# STM32F479xx register map
File version: 1.0
Registers are 32-bit, read-write, reset 0x0 unless marked. A register's access mark holds for its fields unless they carry their own. Offsets are from the block's base; [hi:lo] are bit positions; lines under a group give offsets from that group; {n}, {i} and the like mark numbered series.

## DAC — Digital to Analog Converter
Base 0x40007400
Same registers: DAC1 0x40007400 (alternate view of DAC)
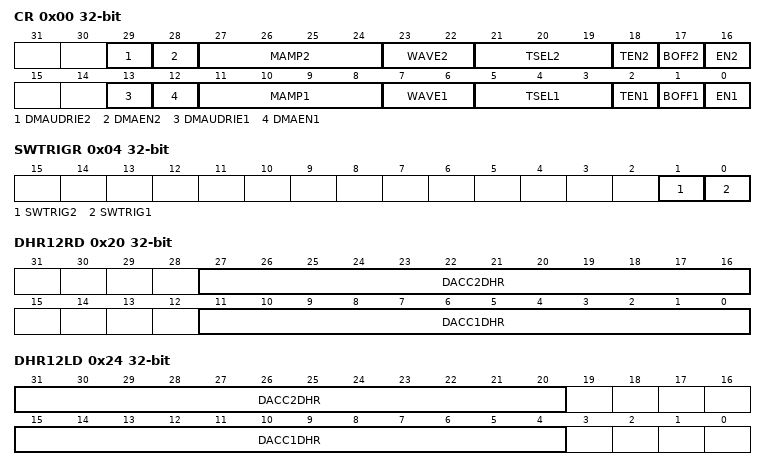
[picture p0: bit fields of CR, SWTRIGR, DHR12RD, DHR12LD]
0x00 CR — DAC control register
  [29] DMAUDRIE2 — DAC channel2 DMA underrun interrupt enable
  [28] DMAEN2 — DAC channel2 DMA enabled
  [27:24] MAMP2 — MAMP2[3:0] (DAC channel2 Mask/Amplitude selector)
  [23:22] WAVE2 — WAVE2[1:0] (DAC channel2 noise/triangle wave generation enable)
  [21:19] TSEL2 — TSEL2[2:0] (DAC channel2 Trigger selection)
  [18] TEN2 — DAC channel2 Trigger enable
  [17] BOFF2 — DAC channel2 output buffer disable
  [16] EN2 — DAC channel2 enable
  [13] DMAUDRIE1 — DAC channel1 DMA underrun interrupt enable
  [12] DMAEN1 — DAC channel1 DMA enable
  [11:8] MAMP1 — MAMP1[3:0] (DAC channel1 Mask/Amplitude selector)
  [7:6] WAVE1 — WAVE1[1:0] (DAC channel1 noise/triangle wave generation enable)
  [5:3] TSEL1 — TSEL1[2:0] (DAC channel1 Trigger selection)
  [2] TEN1 — DAC channel1 Trigger enable
  [1] BOFF1 — DAC channel1 output buffer disable
  [0] EN1 — DAC channel1 enable
0x04 SWTRIGR — DAC software trigger register
  [1] SWTRIG2 — DAC channel2 software trigger
  [0] SWTRIG1 — DAC channel1 software trigger
0x08 DHR12R1 — DAC channel1 12-bit right-aligned data holding register
  [11:0] DACC1DHR — DAC channel1 12-bit Right aligned data
0x0C DHR12L1 — DAC channel1 12-bit left aligned data holding register
  [15:4] DACC1DHR — DAC channel1 12-bit Left aligned data
0x10 DHR8R1 — DAC channel1 8-bit right aligned data holding register
  [7:0] DACC1DHR — DAC channel1 8-bit Right aligned data
0x14 DHR12R2 — DAC channel2 12-bit right aligned data holding register
  [11:0] DACC2DHR — DAC channel2 12-bit Right aligned data
0x18 DHR12L2 — DAC channel2 12-bit left aligned data holding register
  [15:4] DACC2DHR — DAC channel2 12-bit Left aligned data
0x1C DHR8R2 — DAC channel2 8-bit right-aligned data holding register
  [7:0] DACC2DHR — DAC channel2 8-bit Right aligned data
0x20 DHR12RD — Dual DAC 12-bit right-aligned data holding register
  [27:16] DACC2DHR — DAC channel2 12-bit Right aligned data
  [11:0] DACC1DHR — DAC channel1 12-bit Right aligned data
0x24 DHR12LD — DUAL DAC 12-bit left aligned data holding register
  [31:20] DACC2DHR — DAC channel2 12-bit Left aligned data
  [15:4] DACC1DHR — DAC channel1 12-bit Left aligned data
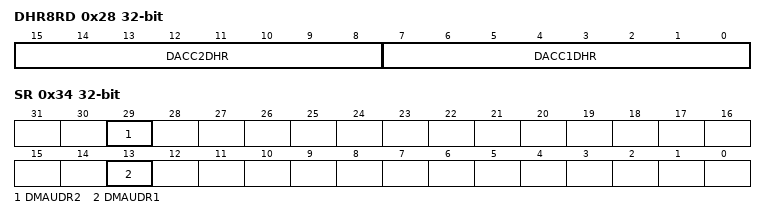
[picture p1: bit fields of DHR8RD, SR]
0x28 DHR8RD — DUAL DAC 8-bit right aligned data holding register
  [15:8] DACC2DHR — DAC channel2 8-bit Right aligned data
  [7:0] DACC1DHR — DAC channel1 8-bit Right aligned data
0x2C DOR1 — DAC channel1 data output register
  [11:0] DACC1DOR — DAC channel1 data output
0x30 DOR2 — DAC channel2 data output register
  [11:0] DACC2DOR — DAC channel2 data output
0x34 SR — DAC status register
  [29] DMAUDR2 — DAC channel2 DMA underrun flag
  [13] DMAUDR1 — DAC channel1 DMA underrun flag

## ADC123_COMMON
Base 0x40012300
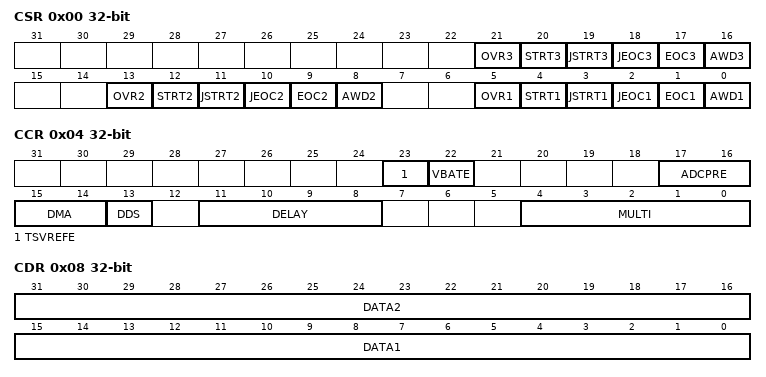
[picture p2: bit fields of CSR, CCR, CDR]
0x00 CSR — ADC Common status register
  [21] OVR3 — ADC3 DMA overrun flag
  [20] STRT3 — ADC3 Regular channel Start flag
  [19] JSTRT3 — ADC3 Injected channel Start flag
  [18] JEOC3 — ADC3 Injected channel end of conversion
  [17] EOC3 — ADC3 End of conversion
  [16] AWD3 — ADC3 Analog watchdog flag
  [13] OVR2 — ADC2 DMA overrun flag
  [12] STRT2 — ADC2 Regular channel Start flag
  [11] JSTRT2 — ADC2 Injected channel Start flag
  [10] JEOC2 — ADC2 Injected channel end of conversion
  [9] EOC2 — ADC2 End of conversion
  [8] AWD2 — ADC2 Analog watchdog flag
  [5] OVR1 — ADC1 DMA overrun flag
  [4] STRT1 — ADC1 Regular channel Start flag
  [3] JSTRT1 — ADC1 Injected channel Start flag
  [2] JEOC1 — ADC1 Injected channel end of conversion
  [1] EOC1 — ADC1 End of conversion
  [0] AWD1 — ADC1 Analog watchdog flag
0x04 CCR — ADC common control register
  [23] TSVREFE — Temperature Sensor and VREFINT Enable
  [22] VBATE — VBAT Enable
  [17:16] ADCPRE — ADCPRE[1:0] bits (ADC prescaler)
    0=DIV2 (ADC synchronous clock derived from AHB clock with prescaler division by 2); 1=DIV4 (ADC synchronous clock derived from AHB clock with prescaler division by 4); 2=DIV6 (ADC synchronous clock derived from AHB clock with prescaler division by 6); 3=DIV8 (ADC synchronous clock derived from AHB clock with prescaler division by 8)
  [15:14] DMA — DMA[1:0] bits (Direct Memory Access mode for multimode)
  [13] DDS — DMA disable selection (Multi-ADC mode)
  [11:8] DELAY — DELAY[3:0] bits (Delay between 2 sampling phases)
    {v}=DELAY_{v+5}CYCLES (ADC multimode delay between two sampling phases: {v+5} ADC clock cycles) (v=0..15)
  [4:0] MULTI — MULTI[4:0] bits (Multi-ADC mode selection)
    0=INDEPENDENT (ADC dual mode disabled (ADC independent mode)); 6=DUAL_REG_SIMULT (ADC dual mode enabled: group regular simultaneous); 7=DUAL_REG_INTERL (ADC dual mode enabled: Combined group regular interleaved); 5=DUAL_INJ_SIMULT (ADC dual mode enabled: group injected simultaneous); 9=DUAL_INJ_ALTERN (ADC dual mode enabled: group injected alternate trigger. Works only with external triggers (not internal SW start)); 1=DUAL_REG_SIM_INJ_SIM (ADC dual mode enabled: Combined group regular simultaneous + group injected simultaneous); 2=DUAL_REG_SIM_INJ_ALT (ADC dual mode enabled: Combined group regular simultaneous + group injected alternate trigger); 3=DUAL_REG_INT_INJ_SIM (ADC dual mode enabled: Combined group regular interleaved + group injected simultaneous); 17=TRIPLE_REG_SIM_INJ_SIM (ADC triple mode enabled: Combined group regular simultaneous + group injected simultaneous); 18=TRIPLE_REG_SIM_INJ_ALT (ADC triple mode enabled: Combined group regular simultaneous + group injected alternate trigger); 21=TRIPLE_INJ_SIMULT (ADC triple mode enabled: group injected simultaneous); 22=TRIPLE_REG_SIMULT (ADC triple mode enabled: group regular simultaneous); 23=TRIPLE_REG_INTERL (ADC triple mode enabled: Combined group regular interleaved)
0x08 CDR — ADC common regular data register for dual AND triple modes
  [31:16] DATA2 — 2nd data of a pair of regular conversions
  [15:0] DATA1 — 1st data of a pair of regular conversions
